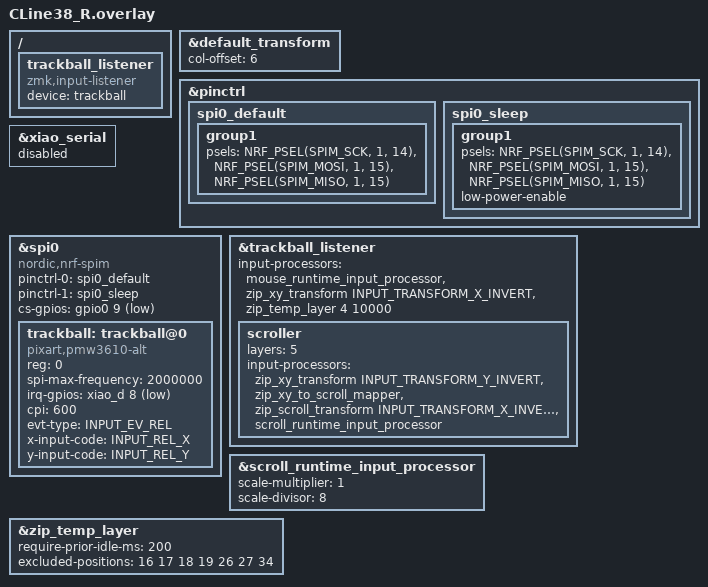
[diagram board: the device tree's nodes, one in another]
#include "CLine38.dtsi"
#include <zephyr/dt-bindings/input/input-event-codes.h>
#include <dt-bindings/zmk/input_transform.h>
#include <input/processors.dtsi>
#include <input/processors/runtime-input-processor.dtsi>
#include <behaviors/battery_history_request.dtsi>

&default_transform {
    col-offset = <6>;
};


/ {
    trackball_listener {
        status = "okay";
        compatible = "zmk,input-listener";
        device = <&trackball>;
    };
};

&pinctrl {
    spi0_default: spi0_default {
        group1 {
            psels = <NRF_PSEL(SPIM_SCK, 1, 14)>,
                <NRF_PSEL(SPIM_MOSI, 1, 15)>,
                <NRF_PSEL(SPIM_MISO, 1, 15)>;
        };
    };

    spi0_sleep: spi0_sleep {
        group1 {
            psels = <NRF_PSEL(SPIM_SCK, 1, 14)>,
                <NRF_PSEL(SPIM_MOSI, 1, 15)>,
                <NRF_PSEL(SPIM_MISO, 1, 15)>;
            low-power-enable;
        };
    };
};


&xiao_serial { status = "disabled"; };

&spi0 {
    status = "okay";
    compatible = "nordic,nrf-spim";
    pinctrl-0 = <&spi0_default>;
    pinctrl-1 = <&spi0_sleep>;
    pinctrl-names = "default", "sleep";
    cs-gpios = <&gpio0 9 GPIO_ACTIVE_LOW>;  //P0.09を指定(CS)

    trackball: trackball@0 {
        status = "okay";
        compatible = "pixart,pmw3610-alt";
        reg = <0>;
        spi-max-frequency = <2000000>;
        irq-gpios = <&xiao_d 8 (GPIO_ACTIVE_LOW | GPIO_PULL_UP)>;
        cpi = <600>;
        //swap-xy;
        evt-type = <INPUT_EV_REL>;
        x-input-code = <INPUT_REL_X>;
        y-input-code = <INPUT_REL_Y>;
    };
};

// Overrides for the input listener node
&trackball_listener {
    status = "okay";
    input-processors = <&mouse_runtime_input_processor>,
        //<&zip_xy_transform INPUT_TRANSFORM_Y_INVERT>,       //Y軸反転
        //<&zip_xy_transform INPUT_TRANSFORM_XY_SWAP>,        //X軸とY軸の入れ替え
        <&zip_xy_transform INPUT_TRANSFORM_X_INVERT>,       //X軸反転
        <&zip_temp_layer 4 10000>;                          //オートマウスレイヤー (MOUSE) を10秒間有効化

    scroller {
        layers = <5>;
        input-processors = 
            // <&zip_xy_transform INPUT_TRANSFORM_XY_SWAP>,        //X軸とY軸の入れ替え
            // <&zip_xy_transform INPUT_TRANSFORM_X_INVERT>,       //X軸反転
            <&zip_xy_transform INPUT_TRANSFORM_Y_INVERT>,       //Y軸反転
            <&zip_xy_to_scroll_mapper>,                         //スクロールモードに変更
            <&zip_scroll_transform INPUT_TRANSFORM_X_INVERT>,   //スクロールのX軸反転
            //<&zip_scroll_transform INPUT_TRANSFORM_Y_INVERT>,   //スクロールのY軸反転
            <&scroll_runtime_input_processor>;                  //スクロール量・軸スナップをDYA Studioから調整可能に
    };
};

// スクロール用のランタイム入力プロセッサ。
//
// 従来の <&zip_scroll_scaler 1 8> を置き換えたもの。scaler は再ビルドしないと
// 変更できなかったが、これに替えるとスクロール量を DYA Studio の
// 「トラックボール設定」から調整できるようになる。あわせて軸スナップ
// (移動を縦横どちらかに固定する機能。表計算ソフトなどで有用) も利用できる。
//
// 注意: このノードは runtime-input-processor.dtsi 内で /omit-if-no-ref/ 指定
// されているため、ここで参照して初めて firmware に組み込まれる。参照が無いと
// DYA Studio のプロセッサ一覧にも現れない。
//
// 下の初期値は従来の <&zip_scroll_scaler 1 8> と同じ 1/8 倍。
// 一度 DYA Studio で変更すると、そちらが保存されて以後優先される。
&scroll_runtime_input_processor {
    scale-multiplier = <1>;
    scale-divisor = <8>;
};

// オートマウスレイヤー。直前200ms以内にキー入力があれば発動しない。
// excluded-positions のキーを押してもレイヤーは解除されない。
// 16-19: MB1/MB3/MB2/SCROLL(hold)  26-27: MB4/MB5  34: 親指Shift
&zip_temp_layer {
    require-prior-idle-ms = <200>;
    excluded-positions = <16 17 18 19 26 27 34>;
};
